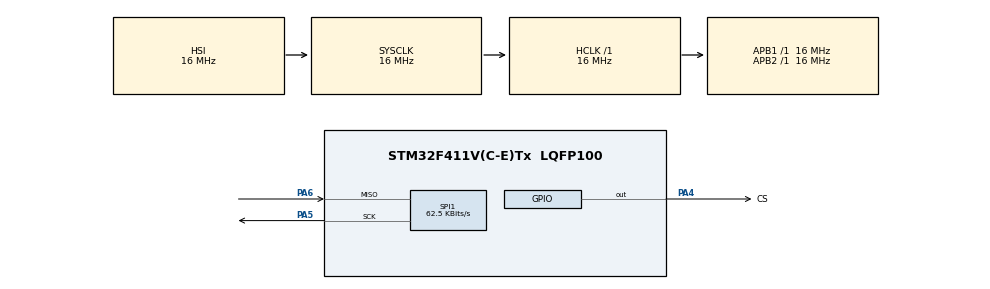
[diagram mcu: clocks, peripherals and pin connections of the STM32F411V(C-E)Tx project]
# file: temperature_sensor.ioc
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ADC1.Channel-0\#ChannelRegularConversion=ADC_CHANNEL_TEMPSENSOR
ADC1.ClockPrescaler=ADC_CLOCK_SYNC_PCLK_DIV8
ADC1.ContinuousConvMode=ENABLE
ADC1.NbrOfConversionFlag=1
ADC1.Rank-0\#ChannelRegularConversion=1
ADC1.SamplingTime-0\#ChannelRegularConversion=ADC_SAMPLETIME_480CYCLES
ADC1.master=1
Mcu.Family=STM32F4
Mcu.Name=STM32F411V(C-E)Tx
Mcu.Package=LQFP100
NVIC.ADC_IRQn=true\:0\:0\:false\:false\:true\:true\:true
NVIC.PriorityGroup=NVIC_PRIORITYGROUP_4
NVIC.SPI1_IRQn=true\:0\:0\:false\:false\:true\:true\:true
PA13.Mode=Serial_Wire
PA13.Signal=SYS_JTMS-SWDIO
PA14.Mode=Serial_Wire
PA14.Signal=SYS_JTCK-SWCLK
PA4.GPIO_Label=CS
PA4.Signal=GPIO_Output
PA5.Mode=RX_Only_Simplex_Unidirect_Master
PA5.Signal=SPI1_SCK
PA6.Mode=RX_Only_Simplex_Unidirect_Master
PA6.Signal=SPI1_MISO
ProjectManager.HeapSize=0x200
ProjectManager.StackSize=0x400
ProjectManager.TargetToolchain=STM32CubeIDE
RCC.AHBFreq_Value=16000000
RCC.APB1Freq_Value=16000000
RCC.APB1TimFreq_Value=16000000
RCC.APB2Freq_Value=16000000
RCC.APB2TimFreq_Value=16000000
RCC.CortexFreq_Value=16000000
RCC.HCLKFreq_Value=16000000
RCC.HSE_VALUE=25000000
RCC.HSI_VALUE=16000000
RCC.LSE_VALUE=32768
RCC.SYSCLKFreq_VALUE=16000000
RCC.VCOOutputFreq_Value=192000000
SPI1.BaudRatePrescaler=SPI_BAUDRATEPRESCALER_256
SPI1.CLKPhase=SPI_PHASE_1EDGE
SPI1.CLKPolarity=SPI_POLARITY_LOW
SPI1.CalculateBaudRate=62.5 KBits/s
SPI1.DataSize=SPI_DATASIZE_16BIT
SPI1.Direction=SPI_DIRECTION_2LINES_RXONLY
SPI1.Mode=SPI_MODE_MASTER
SPI1.VirtualType=VM_MASTER
VP_ADC1_TempSens_Input.Mode=IN-TempSens
board=custom

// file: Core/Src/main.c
/* USER CODE BEGIN Header */
/**
 ******************************************************************************
 * @file           : main.c
 * @brief          : Main program body
 ******************************************************************************
 * @attention
 *
 * <h2><center>&copy; Copyright (c) 2021 STMicroelectronics.
 * All rights reserved.</center></h2>
 *
 * This software component is licensed by ST under BSD 3-Clause license,
 * the "License"; You may not use this file except in compliance with the
 * License. You may obtain a copy of the License at:
 *                        opensource.org/licenses/BSD-3-Clause
 *
 ******************************************************************************
 */
/* USER CODE END Header */
#include "main.h"

ADC_HandleTypeDef hadc1;

SPI_HandleTypeDef hspi1;

/* USER CODE BEGIN PV */

////////////////////////////////////////////////
volatile uint16_t Pomiar_ADC;
volatile float Temperature_ADC;
volatile float Vsense;
// Parametry z dokumentacji do obliczenia temperatury
volatile const float V25 = 0.76;		// Volt
volatile const float Avg_slope = 0.0025;	  // Volts/degree
volatile const float Supply_voltage = 3.0; // Volt
volatile const float ADCResolution = 4096.0; // 2^resolution -> 2^12 = 4096
////////////////////////////////////////////////
float Temperature_SPI = 0;	// odczyt temperatury
uint8_t DATARX[2];		// dane z MAX6675
////////////////////////////////////////////////
/* USER CODE END PV */

void SystemClock_Config(void);
static void MX_GPIO_Init(void);
static void MX_ADC1_Init(void);
static void MX_SPI1_Init(void);
/* USER CODE BEGIN PFP */

// Co się stanie gdy zostanie wywołane przerwanie ADC
void HAL_ADC_ConvCpltCallback(ADC_HandleTypeDef *hadc) {
	Pomiar_ADC = HAL_ADC_GetValue(&hadc1); // otrzymana wartość z przetwornika (To nie jeest w stopniach C)
	Vsense = (Supply_voltage * Pomiar_ADC) / (ADCResolution - 1); // zamiana wartości z czujnika na napięcie
	Temperature_ADC = ((Vsense - V25) / Avg_slope) + 25; // obliczenie temperatury
	HAL_ADC_Start_IT(&hadc1);
}

void SPI_Temperature() {
	HAL_GPIO_WritePin(CS_GPIO_Port, CS_Pin, GPIO_PIN_RESET); 	// Niski stan CS
	HAL_SPI_Receive(&hspi1, DATARX, 1, 50);           // Rozpoczęcie odbioru SPI
	HAL_GPIO_WritePin(CS_GPIO_Port, CS_Pin, GPIO_PIN_SET); // Wysoki stan CS - rozpoczęcia odbioru danych

	Temperature_SPI = ((((DATARX[0] | DATARX[1] << 8))) >> 3); // Przesunięcie bitowe, pobranie tylko wartości temperatury
	Temperature_SPI *= 0.25;                 // zamiana na stopnie Celsjusza
	HAL_Delay(250); // konwersja trwa 220ms ale poczekaj 250 na przyjęcie kolejnej ramki danych
}

/* USER CODE END PFP */

int main(void) {

	/* MCU Configuration--------------------------------------------------------*/

	/* Reset of all peripherals, Initializes the Flash interface and the Systick. */
	HAL_Init();

	/* Configure the system clock */
	SystemClock_Config();

	/* Initialize all configured peripherals */
	MX_GPIO_Init();
	MX_ADC1_Init();
	MX_SPI1_Init();
	/* USER CODE BEGIN 2 */

	HAL_ADC_Start_IT(&hadc1);	// Uruchomienie konwersji przetwornika ADC

	/* USER CODE END 2 */

	/* Infinite loop */
	while (1) {

		/* USER CODE BEGIN 3 */
		SPI_Temperature();

	}
	/* USER CODE END 3 */
}

void SystemClock_Config(void) {
	RCC_OscInitTypeDef RCC_OscInitStruct = { 0 };
	RCC_ClkInitTypeDef RCC_ClkInitStruct = { 0 };

	/** Configure the main internal regulator output voltage
	 */
	__HAL_RCC_PWR_CLK_ENABLE();
	__HAL_PWR_VOLTAGESCALING_CONFIG(PWR_REGULATOR_VOLTAGE_SCALE1);
	/** Initializes the RCC Oscillators according to the specified parameters
	 * in the RCC_OscInitTypeDef structure.
	 */
	RCC_OscInitStruct.OscillatorType = RCC_OSCILLATORTYPE_HSI;
	RCC_OscInitStruct.HSIState = RCC_HSI_ON;
	RCC_OscInitStruct.HSICalibrationValue = RCC_HSICALIBRATION_DEFAULT;
	RCC_OscInitStruct.PLL.PLLState = RCC_PLL_NONE;
	if (HAL_RCC_OscConfig(&RCC_OscInitStruct) != HAL_OK) {
		Error_Handler();
	}
	/** Initializes the CPU, AHB and APB buses clocks
	 */
	RCC_ClkInitStruct.ClockType = RCC_CLOCKTYPE_HCLK | RCC_CLOCKTYPE_SYSCLK
			| RCC_CLOCKTYPE_PCLK1 | RCC_CLOCKTYPE_PCLK2;
	RCC_ClkInitStruct.SYSCLKSource = RCC_SYSCLKSOURCE_HSI;
	RCC_ClkInitStruct.AHBCLKDivider = RCC_SYSCLK_DIV1;
	RCC_ClkInitStruct.APB1CLKDivider = RCC_HCLK_DIV1;
	RCC_ClkInitStruct.APB2CLKDivider = RCC_HCLK_DIV1;

	if (HAL_RCC_ClockConfig(&RCC_ClkInitStruct, FLASH_LATENCY_0) != HAL_OK) {
		Error_Handler();
	}
}

static void MX_ADC1_Init(void) {

	ADC_ChannelConfTypeDef sConfig = { 0 };

	/** Configure the global features of the ADC (Clock, Resolution, Data Alignment and number of conversion)
	 */
	hadc1.Instance = ADC1;
	hadc1.Init.ClockPrescaler = ADC_CLOCK_SYNC_PCLK_DIV8;
	hadc1.Init.Resolution = ADC_RESOLUTION_12B;
	hadc1.Init.ScanConvMode = DISABLE;
	hadc1.Init.ContinuousConvMode = ENABLE;
	hadc1.Init.DiscontinuousConvMode = DISABLE;
	hadc1.Init.ExternalTrigConvEdge = ADC_EXTERNALTRIGCONVEDGE_NONE;
	hadc1.Init.ExternalTrigConv = ADC_SOFTWARE_START;
	hadc1.Init.DataAlign = ADC_DATAALIGN_RIGHT;
	hadc1.Init.NbrOfConversion = 1;
	hadc1.Init.DMAContinuousRequests = DISABLE;
	hadc1.Init.EOCSelection = ADC_EOC_SINGLE_CONV;
	if (HAL_ADC_Init(&hadc1) != HAL_OK) {
		Error_Handler();
	}
	/** Configure for the selected ADC regular channel its corresponding rank in the sequencer and its sample time.
	 */
	sConfig.Channel = ADC_CHANNEL_TEMPSENSOR;
	sConfig.Rank = 1;
	sConfig.SamplingTime = ADC_SAMPLETIME_480CYCLES;
	if (HAL_ADC_ConfigChannel(&hadc1, &sConfig) != HAL_OK) {
		Error_Handler();
	}

}

static void MX_SPI1_Init(void) {

	/* SPI1 parameter configuration*/
	hspi1.Instance = SPI1;
	hspi1.Init.Mode = SPI_MODE_MASTER;
	hspi1.Init.Direction = SPI_DIRECTION_2LINES_RXONLY;
	hspi1.Init.DataSize = SPI_DATASIZE_16BIT;
	hspi1.Init.CLKPolarity = SPI_POLARITY_LOW;
	hspi1.Init.CLKPhase = SPI_PHASE_1EDGE;
	hspi1.Init.NSS = SPI_NSS_SOFT;
	hspi1.Init.BaudRatePrescaler = SPI_BAUDRATEPRESCALER_256;
	hspi1.Init.FirstBit = SPI_FIRSTBIT_MSB;
	hspi1.Init.TIMode = SPI_TIMODE_DISABLE;
	hspi1.Init.CRCCalculation = SPI_CRCCALCULATION_DISABLE;
	hspi1.Init.CRCPolynomial = 10;
	if (HAL_SPI_Init(&hspi1) != HAL_OK) {
		Error_Handler();
	}

}

static void MX_GPIO_Init(void) {
	GPIO_InitTypeDef GPIO_InitStruct = { 0 };

	/* GPIO Ports Clock Enable */
	__HAL_RCC_GPIOA_CLK_ENABLE();

	/*Configure GPIO pin Output Level */
	HAL_GPIO_WritePin(CS_GPIO_Port, CS_Pin, GPIO_PIN_RESET);

	/*Configure GPIO pin : CS_Pin */
	GPIO_InitStruct.Pin = CS_Pin;
	GPIO_InitStruct.Mode = GPIO_MODE_OUTPUT_PP;
	GPIO_InitStruct.Pull = GPIO_NOPULL;
	GPIO_InitStruct.Speed = GPIO_SPEED_FREQ_LOW;
	HAL_GPIO_Init(CS_GPIO_Port, &GPIO_InitStruct);

}

void Error_Handler(void) {
	__disable_irq();
	while (1) {
	}
}

/************************ (C) COPYRIGHT STMicroelectronics *****END OF FILE****/
